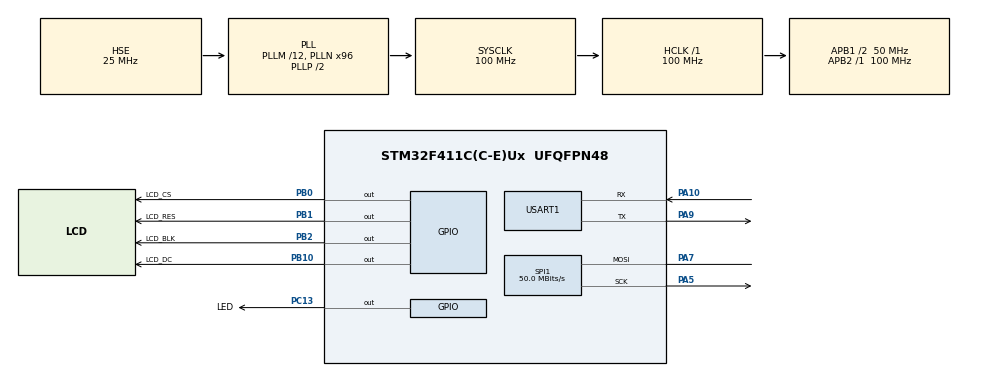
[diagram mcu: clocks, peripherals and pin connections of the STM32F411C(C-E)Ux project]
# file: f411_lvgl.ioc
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Dma.Request0=SPI1_TX
Dma.SPI1_TX.0.Direction=DMA_MEMORY_TO_PERIPH
Dma.SPI1_TX.0.FIFOMode=DMA_FIFOMODE_DISABLE
Dma.SPI1_TX.0.Instance=DMA2_Stream2
Dma.SPI1_TX.0.MemDataAlignment=DMA_MDATAALIGN_BYTE
Dma.SPI1_TX.0.MemInc=DMA_MINC_ENABLE
Dma.SPI1_TX.0.Mode=DMA_NORMAL
Dma.SPI1_TX.0.PeriphDataAlignment=DMA_PDATAALIGN_BYTE
Dma.SPI1_TX.0.PeriphInc=DMA_PINC_DISABLE
Dma.SPI1_TX.0.Priority=DMA_PRIORITY_LOW
Mcu.Family=STM32F4
Mcu.Name=STM32F411C(C-E)Ux
Mcu.Package=UFQFPN48
NVIC.DMA2_Stream2_IRQn=true\:0\:0\:false\:false\:true\:false\:true\:true
NVIC.PriorityGroup=NVIC_PRIORITYGROUP_4
NVIC.TIM3_IRQn=true\:0\:0\:false\:false\:true\:true\:true\:true
PA10.Mode=Asynchronous
PA10.Signal=USART1_RX
PA13.Mode=Serial_Wire
PA13.Signal=SYS_JTMS-SWDIO
PA14.Mode=Serial_Wire
PA14.Signal=SYS_JTCK-SWCLK
PA5.Mode=Simplex_Bidirectional_Master
PA5.Signal=SPI1_SCK
PA7.Mode=Simplex_Bidirectional_Master
PA7.Signal=SPI1_MOSI
PA9.Mode=Asynchronous
PA9.Signal=USART1_TX
PB0.GPIO_Label=LCD_CS
PB0.GPIO_PuPd=GPIO_PULLUP
PB0.GPIO_Speed=GPIO_SPEED_FREQ_VERY_HIGH
PB0.PinState=GPIO_PIN_SET
PB0.Signal=GPIO_Output
PB1.GPIO_Label=LCD_RES
PB1.Signal=GPIO_Output
PB10.GPIO_Label=LCD_DC
PB10.GPIO_Speed=GPIO_SPEED_FREQ_VERY_HIGH
PB10.Signal=GPIO_Output
PB2.GPIO_Label=LCD_BLK
PB2.Signal=GPIO_Output
PC13-ANTI_TAMP.GPIO_Label=LED
PC13-ANTI_TAMP.Signal=GPIO_Output
PH0\ -\ OSC_IN.Mode=HSE-External-Oscillator
PH0\ -\ OSC_IN.Signal=RCC_OSC_IN
PH1\ -\ OSC_OUT.Mode=HSE-External-Oscillator
PH1\ -\ OSC_OUT.Signal=RCC_OSC_OUT
ProjectManager.HeapSize=0x200
ProjectManager.StackSize=0x400
ProjectManager.TargetToolchain=STM32CubeIDE
RCC.48MHZClocksFreq_Value=50000000
RCC.AHBFreq_Value=100000000
RCC.APB1CLKDivider=RCC_HCLK_DIV2
RCC.APB1Freq_Value=50000000
RCC.APB1TimFreq_Value=100000000
RCC.APB2Freq_Value=100000000
RCC.APB2TimFreq_Value=100000000
RCC.CortexFreq_Value=100000000
RCC.HCLKFreq_Value=100000000
RCC.HSE_VALUE=25000000
RCC.HSI_VALUE=16000000
RCC.LSE_VALUE=32768
RCC.PLLM=12
RCC.PLLN=96
RCC.PLLSourceVirtual=RCC_PLLSOURCE_HSE
RCC.SYSCLKFreq_VALUE=100000000
RCC.SYSCLKSource=RCC_SYSCLKSOURCE_PLLCLK
RCC.VCOOutputFreq_Value=200000000
SPI1.BaudRatePrescaler=SPI_BAUDRATEPRESCALER_2
SPI1.CLKPolarity=SPI_POLARITY_HIGH
SPI1.CalculateBaudRate=50.0 MBits/s
SPI1.Direction=SPI_DIRECTION_1LINE
SPI1.Mode=SPI_MODE_MASTER
SPI1.VirtualType=VM_MASTER
TIM3.Period=1000-1
TIM3.Prescaler=99
USART1.VirtualMode=VM_ASYNC
VP_TIM3_VS_ClockSourceINT.Mode=Internal
board=custom

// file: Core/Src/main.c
/* USER CODE BEGIN Header */
/**
  ******************************************************************************
  * @file           : main.c
  * @brief          : Main program body
  ******************************************************************************
  * @attention
  *
  * Copyright (c) 2023 STMicroelectronics.
  * All rights reserved.
  *
  * This software is licensed under terms that can be found in the LICENSE file
  * in the root directory of this software component.
  * If no LICENSE file comes with this software, it is provided AS-IS.
  *
  ******************************************************************************
  */
/* USER CODE END Header */
#include "main.h"
#include "dma.h"
#include "spi.h"
#include "tim.h"
#include "usart.h"
#include "gpio.h"

/* USER CODE BEGIN Includes */
#include "lcd.h"
#include "lvgl.h"
#include "lv_conf.h"
#include "../../lvgl/examples/porting/lv_port_disp_template.h"
#include "../../lvgl/demos/benchmark/lv_demo_benchmark.h"
/* USER CODE END Includes */

void SystemClock_Config(void);

int main(void)
{

  /* MCU Configuration--------------------------------------------------------*/

  /* Reset of all peripherals, Initializes the Flash interface and the Systick. */
  HAL_Init();

  /* Configure the system clock */
  SystemClock_Config();

  /* Initialize all configured peripherals */
  MX_GPIO_Init();
  MX_DMA_Init();
  MX_SPI1_Init();
  MX_TIM3_Init();
  MX_USART1_UART_Init();
  /* USER CODE BEGIN 2 */

/*   lcd_init();
  lcd_fill(0,280,0,240,BROWN);
  BACKCOLOR = BROWN;
  POINT = WHITE;
  lcd_showstr(50,50,16,0,(uint8_t*)"STM32F411 LVGL"); */

  HAL_TIM_Base_Start_IT(&htim3);
  lv_init();
  lv_port_disp_init();
  lv_demo_benchmark();
  /* USER CODE END 2 */

  /* Infinite loop */
  while (1) {

    /* USER CODE BEGIN 3 */
    lv_timer_handler();
    HAL_Delay(5);
  }
  /* USER CODE END 3 */
}

void SystemClock_Config(void)
{
  RCC_OscInitTypeDef RCC_OscInitStruct = {0};
  RCC_ClkInitTypeDef RCC_ClkInitStruct = {0};

  /** Configure the main internal regulator output voltage
  */
  __HAL_RCC_PWR_CLK_ENABLE();
  __HAL_PWR_VOLTAGESCALING_CONFIG(PWR_REGULATOR_VOLTAGE_SCALE1);

  /** Initializes the RCC Oscillators according to the specified parameters
  * in the RCC_OscInitTypeDef structure.
  */
  RCC_OscInitStruct.OscillatorType = RCC_OSCILLATORTYPE_HSE;
  RCC_OscInitStruct.HSEState = RCC_HSE_ON;
  RCC_OscInitStruct.PLL.PLLState = RCC_PLL_ON;
  RCC_OscInitStruct.PLL.PLLSource = RCC_PLLSOURCE_HSE;
  RCC_OscInitStruct.PLL.PLLM = 12;
  RCC_OscInitStruct.PLL.PLLN = 96;
  RCC_OscInitStruct.PLL.PLLP = RCC_PLLP_DIV2;
  RCC_OscInitStruct.PLL.PLLQ = 4;
  if (HAL_RCC_OscConfig(&RCC_OscInitStruct) != HAL_OK)
  {
    Error_Handler();
  }

  /** Initializes the CPU, AHB and APB buses clocks
  */
  RCC_ClkInitStruct.ClockType = RCC_CLOCKTYPE_HCLK|RCC_CLOCKTYPE_SYSCLK
                              |RCC_CLOCKTYPE_PCLK1|RCC_CLOCKTYPE_PCLK2;
  RCC_ClkInitStruct.SYSCLKSource = RCC_SYSCLKSOURCE_PLLCLK;
  RCC_ClkInitStruct.AHBCLKDivider = RCC_SYSCLK_DIV1;
  RCC_ClkInitStruct.APB1CLKDivider = RCC_HCLK_DIV2;
  RCC_ClkInitStruct.APB2CLKDivider = RCC_HCLK_DIV1;

  if (HAL_RCC_ClockConfig(&RCC_ClkInitStruct, FLASH_LATENCY_3) != HAL_OK)
  {
    Error_Handler();
  }
}

/* USER CODE BEGIN 4 */
void HAL_TIM_PeriodElapsedCallback(TIM_HandleTypeDef *htim)
{
  if (htim->Instance == TIM3) {
    lv_tick_inc(1);
    //printf("time3 coming \r\n");
  }
}
/* USER CODE END 4 */

void Error_Handler(void)
{
  __disable_irq();
  while (1) {
  }
}
